VERSION ""

NS_ :

BS_:

BU_: Device Host

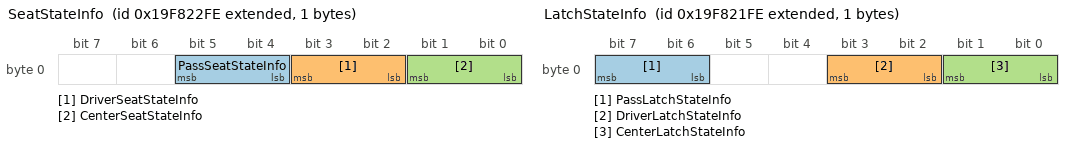
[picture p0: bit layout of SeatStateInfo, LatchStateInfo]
BO_ 2583175934 SeatStateInfo: 1 Vector__XXX
 SG_ PassSeatStateInfo : 4|2@1+ (1,0) [0|3] "" Vector__XXX
 SG_ DriverSeatStateInfo : 2|2@1+ (1,0) [0|3] "" Vector__XXX
 SG_ CenterSeatStateInfo : 0|2@1+ (1,0) [0|3] "" Vector__XXX

BO_ 2583175678 LatchStateInfo: 1 Vector__XXX
 SG_ PassLatchStateInfo : 6|2@1+ (1,0) [0|3] "" Vector__XXX
 SG_ DriverLatchStateInfo : 2|2@1+ (1,0) [0|3] "" Vector__XXX
 SG_ CenterLatchStateInfo : 0|2@1+ (1,0) [0|3] "" Vector__XXX

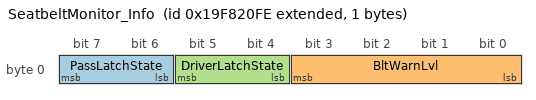
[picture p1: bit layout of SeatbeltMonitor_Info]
BO_ 2583175422 SeatbeltMonitor_Info: 1 Vector__XXX
 SG_ PassLatchState : 6|2@1+ (1,0) [0|3] "" Vector__XXX
 SG_ BltWarnLvl : 0|4@1+ (1,0) [0|9] "" Vector__XXX
 SG_ DriverLatchState : 4|2@1+ (1,0) [0|3] "" Vector__XXX

CM_ "$File: //depot/auto/dbc/Software_Modules/Safety_System/SEATBELT/0.3.2.0/SEATBELT.dbc $
$Change: 215984 $
$DateTime: 2024/08/21 10:11:36 $
$Revision: #1 $";
CM_ BO_ 2583175934 "Message with information from seatbelts and seatmats monitor";
CM_ SG_ 2583175934 PassSeatStateInfo "Passenger seatmat state";
CM_ SG_ 2583175934 DriverSeatStateInfo "Driver seatmat state";
CM_ SG_ 2583175934 CenterSeatStateInfo "Center passenger seatmat state";
CM_ BO_ 2583175678 "Message with information from seatbelts and seatmats monitor";
CM_ SG_ 2583175678 PassLatchStateInfo "Passenger seatbelt fastener and seatmat combined state";
CM_ SG_ 2583175678 DriverLatchStateInfo "Driver seatbelt fastener and seatmat combined state";
CM_ SG_ 2583175678 CenterLatchStateInfo "Center passenger seatbelt fastener state";
CM_ BO_ 2583175422 "Message with information from seatbelts and seatmats monitor";
CM_ SG_ 2583175422 PassLatchState "Passenger seatbelt fastener and seatmat combined state";
CM_ SG_ 2583175422 BltWarnLvl "Seatbelt minder warning level for driver and passenger.";
CM_ SG_ 2583175422 DriverLatchState "Driver seatbelt fastener and seatmat combined state";
BA_DEF_  "BusType" STRING ;
BA_DEF_  "DBName" STRING ;
BA_DEF_  "DatabaseVersion" STRING ;
BA_DEF_ BO_  "GenMsgCycleTime" INT 0 3600000;
BA_DEF_ BO_  "GenMsgDelayTime" INT 0 1000;
BA_DEF_ BO_  "GenMsgILSupport" ENUM  "No","Yes";
BA_DEF_ BO_  "GenMsgRequestable" INT 0 1;
BA_DEF_ BO_  "GenMsgSendType" ENUM  "cyclic","NotUsed","NotUsed","NotUsed","NotUsed","NotUsed","NotUsed","IfActive","noMsgSendType";
BA_DEF_ SG_  "GenSigEVName" STRING ;
BA_DEF_ SG_  "GenSigILSupport" ENUM  "No","Yes";
BA_DEF_ SG_  "GenSigSendType" ENUM  "Cyclic","OnWrite","OnWriteWithRepetition","OnChange","OnChangeWithRepetition","IfActive","IfActiveWithRepetition","NoSigSendType";
BA_DEF_ SG_  "GenSigStartValue" INT 0 2147483647;
BA_DEF_ BU_  "NmStationAddress" INT 0 255;
BA_DEF_  "ProtocolType" STRING ;
BA_DEF_  "SAE_J1939_21_SpecVersion" STRING ;
BA_DEF_  "SAE_J1939_71_SpecVersion" STRING ;
BA_DEF_  "SAE_J1939_73_SpecVersion" STRING ;
BA_DEF_  "SAE_J1939_75_SpecVersion" STRING ;
BA_DEF_  "SAE_J1939_81_SpecVersion" STRING ;
BA_DEF_  "SAE_J1939_DA_SpecVersion" STRING ;
BA_DEF_ BO_  "SendOnChange" ENUM  "No","Yes";
BA_DEF_ SG_  "SigType" ENUM  "Default","Range","RangeSigned","ASCII","Discrete","Control","ReferencePGN","DTC","StringDelimiter","StringLength","StringLengthControl","MessageCounter","MessageChecksum";
BA_DEF_ BO_  "VFrameFormat" ENUM  "StandardCAN","ExtendedCAN","reserved","J1939PG","reserved","reserved","reserved","reserved","reserved","reserved","reserved","reserved","reserved","reserved","StandardCAN_FD","ExtendedCAN_FD";
BA_DEF_ BO_  "Producer" STRING ;
BA_DEF_DEF_  "BusType" "";
BA_DEF_DEF_  "DBName" "";
BA_DEF_DEF_  "DatabaseVersion" "";
BA_DEF_DEF_  "GenMsgCycleTime" 0;
BA_DEF_DEF_  "GenMsgDelayTime" 0;
BA_DEF_DEF_  "GenMsgILSupport" "Yes";
BA_DEF_DEF_  "GenMsgRequestable" 1;
BA_DEF_DEF_  "GenMsgSendType" "noMsgSendType";
BA_DEF_DEF_  "GenSigEVName" "Env@Nodename_@Signame";
BA_DEF_DEF_  "GenSigILSupport" "Yes";
BA_DEF_DEF_  "GenSigSendType" "NoSigSendType";
BA_DEF_DEF_  "GenSigStartValue" 0;
BA_DEF_DEF_  "NmStationAddress" 254;
BA_DEF_DEF_  "ProtocolType" "";
BA_DEF_DEF_  "SAE_J1939_21_SpecVersion" "";
BA_DEF_DEF_  "SAE_J1939_71_SpecVersion" "";
BA_DEF_DEF_  "SAE_J1939_73_SpecVersion" "";
BA_DEF_DEF_  "SAE_J1939_75_SpecVersion" "";
BA_DEF_DEF_  "SAE_J1939_81_SpecVersion" "";
BA_DEF_DEF_  "SAE_J1939_DA_SpecVersion" "";
BA_DEF_DEF_  "SendOnChange" "No";
BA_DEF_DEF_  "SigType" "Default";
BA_DEF_DEF_  "VFrameFormat" "J1939PG";
BA_DEF_DEF_  "Producer" "";
BA_ "BusType" "CAN";
BA_ "DatabaseVersion" "1.0";
BA_ "ProtocolType" "J1939";
BA_ "SAE_J1939_21_SpecVersion" "2006-10";
BA_ "SAE_J1939_71_SpecVersion" "2012-10";
BA_ "SAE_J1939_73_SpecVersion" "2012-10";
BA_ "SAE_J1939_75_SpecVersion" "2012-05";
BA_ "SAE_J1939_81_SpecVersion" "2012-05";
BA_ "SAE_J1939_DA_SpecVersion" "2015-01";
BA_ "DBName" "SEATBELT";
BA_ "Producer" BO_ 2583175934 "SFT";
BA_ "GenMsgCycleTime" BO_ 2583175934 1000;
BA_ "GenMsgSendType" BO_ 2583175934 0;
BA_ "GenMsgDelayTime" BO_ 2583175934 100;
BA_ "SendOnChange" BO_ 2583175934 1;
BA_ "Producer" BO_ 2583175678 "SFT";
BA_ "GenMsgCycleTime" BO_ 2583175678 1000;
BA_ "GenMsgSendType" BO_ 2583175678 0;
BA_ "GenMsgDelayTime" BO_ 2583175678 100;
BA_ "SendOnChange" BO_ 2583175678 1;
BA_ "Producer" BO_ 2583175422 "SFT";
BA_ "GenMsgSendType" BO_ 2583175422 0;
BA_ "GenMsgCycleTime" BO_ 2583175422 1000;
BA_ "GenMsgDelayTime" BO_ 2583175422 100;
BA_ "SendOnChange" BO_ 2583175422 1;
BA_ "GenSigStartValue" SG_ 2583175934 PassSeatStateInfo 3;
BA_ "GenSigStartValue" SG_ 2583175934 DriverSeatStateInfo 3;
BA_ "GenSigStartValue" SG_ 2583175934 CenterSeatStateInfo 3;
BA_ "GenSigStartValue" SG_ 2583175678 PassLatchStateInfo 3;
BA_ "GenSigStartValue" SG_ 2583175678 DriverLatchStateInfo 3;
BA_ "GenSigStartValue" SG_ 2583175678 CenterLatchStateInfo 3;
BA_ "GenSigStartValue" SG_ 2583175422 PassLatchState 3;
BA_ "GenSigStartValue" SG_ 2583175422 DriverLatchState 3;
VAL_ 2583175934 PassSeatStateInfo 3 "NA" 2 "Error" 1 "Occpd" 0 "Free" ;
VAL_ 2583175934 DriverSeatStateInfo 3 "NA" 2 "Error" 1 "Occpd" 0 "Free" ;
VAL_ 2583175934 CenterSeatStateInfo 3 "NA" 2 "Error" 1 "Occpd" 0 "Free" ;
VAL_ 2583175678 PassLatchStateInfo 3 "NA" 2 "Error" 1 "On" 0 "Off" ;
VAL_ 2583175678 DriverLatchStateInfo 3 "NA" 2 "Error" 1 "On" 0 "Off" ;
VAL_ 2583175678 CenterLatchStateInfo 3 "NA" 2 "Error" 1 "On" 0 "Off" ;
VAL_ 2583175422 PassLatchState 3 "NA" 2 "Error" 1 "On" 0 "Off" ;
VAL_ 2583175422 BltWarnLvl 9 "FinalWarnBoth" 8 "FinalWarnPass" 7 "FinalWarnDrvr" 6 "SecondWarnBoth" 5 "SecondWarnPass" 4 "SecondWarnDrvr" 3 "FirstWarnBoth" 2 "FirstWarnPass" 1 "FirstWarnDrvr" 0 "NoWarn" ;
VAL_ 2583175422 DriverLatchState 3 "NA" 2 "Error" 1 "On" 0 "Off" ;
